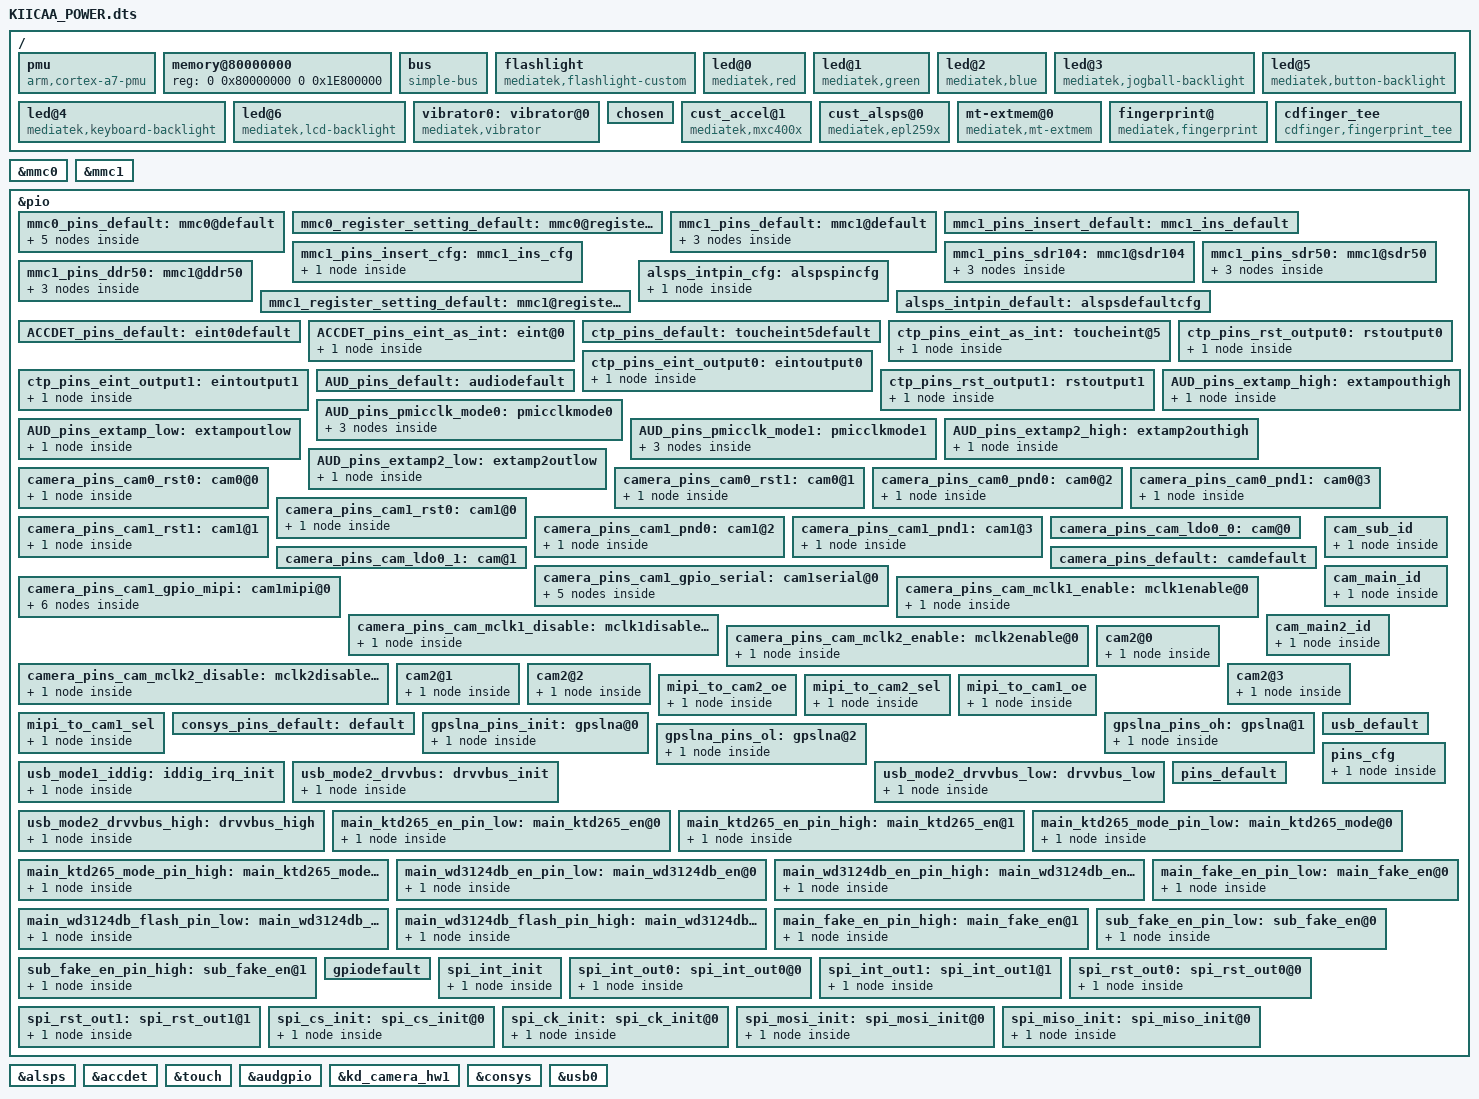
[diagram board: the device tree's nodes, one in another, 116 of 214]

/dts-v1/;

#include "mt6580.dtsi"

/ {
	pmu {
		compatible = "arm,cortex-a7-pmu";
		interrupts = <0x0 0x4 0x8 0x0 0x5 0x8 0x0 0x6 0x8 0x0 0x7 0x8>;
	};

	memory@80000000 {
		device_type = "memory";
		reg = <0 0x80000000 0 0x1E800000>;
	};

	bus {
		compatible = "simple-bus";
		#address-cells = <1>;
		#size-cells = <1>;
		ranges = <0 0 0 0xffffffff>;
	};
	flashlight:flashlight {
		compatible = "mediatek,flashlight-custom";
	};
	led@0 {
		compatible = "mediatek,red";
		led_mode = <3>;
		data = <2>;
		pwm_config = <0 0 0 0 0>;
	};
	led@1 {
		compatible = "mediatek,green";
		led_mode = <3>;
		data = <2>;
		pwm_config = <0 0 0 0 0>;
	};
	led@2 {
		compatible = "mediatek,blue";
		led_mode = <3>;
		data = <2>;
		pwm_config = <0 0 0 0 0>;
	};
	led@3 {
		compatible = "mediatek,jogball-backlight";
		led_mode = <0>;
		data = <1>;
		pwm_config = <0 0 0 0 0>;
	};
	led@4 {
		compatible = "mediatek,keyboard-backlight";
		led_mode = <0>;
		data = <1>;
		pwm_config = <0 0 0 0 0>;
	};
	led@5 {
		compatible = "mediatek,button-backlight";
		led_mode = <3>;
		data = <1>;
		pwm_config = <0 0 0 0 0>;
	};
	led@6 {
		compatible = "mediatek,lcd-backlight";
		led_mode = <5>;
		data = <1>;
		pwm_config = <0 0 0 0 0>;
	};

	vibrator0:vibrator@0 {
		compatible = "mediatek,vibrator";
		vib_timer = <25>;
		vib_limit = <9>;
		vib_vol= <6>;
	};

	   /* chosen */
	   chosen {
	bootargs = "console=tty0 console=ttyMT0,921600n1 root=/dev/ram initrd=0x84000000,0x400000 loglevel=8";
		/* fpga may has no lk, we need to specify display info here */
		/* fb buffer is reserved using this dts by memory node above */
		atag,videolfb-fb_base = <0x9E800000>;
		atag,videolfb-islcmfound = <1>;
		atag,videolfb-fps= <6000>;
		atag,videolfb-vramSize= <0x01800000>;
		atag,videolfb-lcmname= "nt35590_AUO";
	   };
	 /*  start sensor */
	cust_accel@1 {
		compatible = "mediatek,mxc400x";
		i2c_num 	= <0x2>;
		i2c_addr 	= <0x15 0x0 0x0 0x0>;
		direction 	= <0x3>;
		power_id 	= <0xffff>;
		power_vol 	= <0x0>;
		firlen 		= <0x0>;
		is_batch_supported = <0x0>;
	};

	cust_alsps@0 {
		compatible = "mediatek,epl259x";
		i2c_num = <0x2>;
		i2c_addr = <0x49 0x0 0x0 0x0>;
		polling_mode_ps = <0x0>;
		polling_mode_als = <0x1>;
		power_id = <0xffff>;
		power_vol = <0x0>;
		als_level = <0x0 0x7d 0x13f 0x20d 0x443 0x9b0 0xbf2 0x13fb 0x218d 0x2a11 0x3239 0x458f 0x564b 0xffff 0xffff>;
		als_value = <0x0 0x85 0x12f 0x1f8 0x3ea 0x7d3 0xbbe 0x138b 0x1f42 0x2710 0x2ee0 0x3e80 0x4e20 0x4e20 0x4e20 0x4e20>;
		ps_threshold_high = <0x1a>;
		ps_threshold_low = <0x15>;
		is_batch_supported_ps = <0x0>;
		is_batch_supported_als = <0x0>;
		ps_integration_time = <0x24>;
	};

	 /* end sensor */

	mt-extmem@0 {
		compatible = "mediatek,mt-extmem";
	};
	fingerprint@ {
		compatible = "mediatek,fingerprint";
		vfingerprint-supply = <0xe>;
		pinctrl-names = "default", "state_spi_eint_init", "state_eint_pull_down", "state_eint_pull_disable", "state_spi_rst_low", "state_spi_rst_high", "state_spi_cs_init", "state_spi_ck_init", "state_spi_mosi_init", "state_spi_miso_init";
		pinctrl-0 = <&gpiodefault>;
		pinctrl-1 = <&spi_int_init>;
		pinctrl-2 = <&spi_int_out0>;
		pinctrl-3 = <&spi_int_out1>;
		pinctrl-4 = <&spi_rst_out0>;
		pinctrl-5 = <&spi_int_out1>;
		pinctrl-6 = <&spi_cs_init>;
		pinctrl-7 = <&spi_ck_init>;
		pinctrl-8 = <&spi_mosi_init>;
		pinctrl-9 = <&spi_miso_init>;
		interrupt-parent = <&eintc>;
		interrupts = <0xf 0x2>;
		debounce = <0xf 0x0>;
		status = "okay";
	};

	cdfinger_tee {
		compatible = "cdfinger,fingerprint_tee";
	};
};

#include "KIICAA_POWER_bat_setting.dtsi"
/* mmc start */
&mmc0 {
	clk_src = /bits/ 8 <MSDC0_CLKSRC_208MHZ>;
	bus-width = <8>;
	max-frequency = <208000000>;
	cap-mmc-highspeed;
	msdc-sys-suspend;
	mmc-hs200-1_8v;
	non-removable;
	pinctl = <&mmc0_pins_default>;
	register_setting = <&mmc0_register_setting_default>;
	host_function = /bits/ 8 <MSDC_EMMC>;
	bootable;
	status = "okay";
};

&mmc1 {
	clk_src = /bits/ 8 <MSDC1_CLKSRC_187MHZ>;
	bus-width = <4>;
	max-frequency = <208000000>;
	msdc-sys-suspend;
	cap-sd-highspeed;
	sd-uhs-sdr12;
	sd-uhs-sdr25;
	sd-uhs-sdr50;
	sd-uhs-sdr104;
	pinctrl-names = "default","insert_cfg";
	pinctrl-0 = <&mmc1_pins_insert_default>;
	pinctrl-1 = <&mmc1_pins_insert_cfg>;
	pinctl = <&mmc1_pins_default>;
	pinctl_sdr104 = <&mmc1_pins_sdr104>;
	pinctl_sdr50 = <&mmc1_pins_sdr50>;
	pinctl_ddr50 = <&mmc1_pins_ddr50>;
	register_setting = <&mmc1_register_setting_default>;
	host_function = /bits/ 8 <MSDC_SD>;
	cd_level = /bits/ 8 <MSDC_CD_LOW>;
	cd-gpios = <&pio 3 0>;
	status = "okay";
	non-removable;
};

&pio {
	mmc0_pins_default: mmc0@default {
		pins_cmd {
			drive-strength = /bits/ 8 <2>;
		};
		pins_dat {
			drive-strength = /bits/ 8 <2>;
		};
		pins_clk {
			drive-strength = /bits/ 8 <2>;
		};
		pins_rst {
			drive-strength = /bits/ 8 <2>;
		};
		pins_ds {
			drive-strength = /bits/ 8 <2>;
		};
	};

	mmc0_register_setting_default: mmc0@register_default {
		dat0rddly      = /bits/ 8 <0>;
		dat1rddly      = /bits/ 8 <0>;
		dat2rddly      = /bits/ 8 <0>;
		dat3rddly      = /bits/ 8 <0>;
		dat4rddly      = /bits/ 8 <0>;
		dat5rddly      = /bits/ 8 <0>;
		dat6rddly      = /bits/ 8 <0>;
		dat7rddly      = /bits/ 8 <0>;
		datwrddly      = /bits/ 8 <0>;
		cmdrrddly      = /bits/ 8 <0>;
		cmdrddly       = /bits/ 8 <0>;
		cmd_edge = /bits/ 8 <MSDC_SMPL_FALLING>;
		rdata_edge = /bits/ 8 <MSDC_SMPL_FALLING>;
		wdata_edge = /bits/ 8 <MSDC_SMPL_FALLING>;

		ett-hs200-cells = <12>;
		ett-hs200-default = <OFFSET_MSDC_PATCH_BIT0	MSDC_PB0_INT_DAT_LATCH_CK_SEL 0x0
			OFFSET_MSDC_PATCH_BIT0  MSDC_PB0_CKGEN_MSDC_DLY_SEL   0x0
			OFFSET_MSDC_PATCH_BIT1  MSDC_PB1_CMD_RSP_TA_CNTR      0x1
			OFFSET_MSDC_IOCON       MSDC_IOCON_RSPL               0x1
			OFFSET_MSDC_PAD_TUNE0   MSDC_PAD_TUNE0_CMDRDLY        0x0
			OFFSET_MSDC_PAD_TUNE0   MSDC_PAD_TUNE0_CMDRRDLY       0x0
			OFFSET_MSDC_PATCH_BIT1  MSDC_PB1_WRDAT_CRCS_TA_CNTR   0x1
			OFFSET_MSDC_PAD_TUNE0   MSDC_PAD_TUNE0_DATWRDLY       0x0
			OFFSET_MSDC_IOCON       MSDC_IOCON_W_D_SMPL           0x1
			OFFSET_MSDC_DAT_RDDLY0  MSDC_DAT_RDDLY0_D0            0x0
			OFFSET_MSDC_PAD_TUNE0   MSDC_PAD_TUNE0_DATRRDLY       0x0
			OFFSET_MSDC_PATCH_BIT0  MSDC_PB0_RD_DAT_SEL           0x1>;
	};

	mmc1_pins_default: mmc1@default {
		pins_cmd {
			drive-strength = /bits/ 8 <3>;
		};
		pins_dat {
			drive-strength = /bits/ 8 <3>;
		};
		pins_clk {
			drive-strength = /bits/ 8 <3>;
		};
	};

	mmc1_pins_insert_default: mmc1_ins_default {
	};

	mmc1_pins_insert_cfg: mmc1_ins_cfg {
		pins_insert {
			pins = <PINMUX_GPIO34__FUNC_GPIO34>;
			input-schmitt-enable =<1>;
			slew-rate = <0>;
			bias-pull-up =<00>;
		};
	};

	mmc1_pins_sdr104: mmc1@sdr104 {
		pins_cmd {
			drive-strength = /bits/ 8 <2>;
		};
		pins_dat {
			drive-strength = /bits/ 8 <2>;
		};
		pins_clk {
			drive-strength = /bits/ 8 <3>;
		};
	};

	mmc1_pins_sdr50: mmc1@sdr50 {
		pins_cmd {
			drive-strength = /bits/ 8 <2>;
		};
		pins_dat {
			drive-strength = /bits/ 8 <2>;
		};
		pins_clk {
			drive-strength = /bits/ 8 <3>;
		};
	};

	mmc1_pins_ddr50: mmc1@ddr50 {
		pins_cmd {
			drive-strength = /bits/ 8 <2>;
		};
		pins_dat {
			drive-strength = /bits/ 8 <2>;
		};
		pins_clk {
			drive-strength = /bits/ 8 <3>;
		};
	};

	mmc1_register_setting_default: mmc1@register_default {
		dat0rddly      = /bits/ 8 <0>;
		dat1rddly      = /bits/ 8 <0>;
		dat2rddly      = /bits/ 8 <0>;
		dat3rddly      = /bits/ 8 <0>;
		datwrddly      = /bits/ 8 <0>;
		cmdrrddly      = /bits/ 8 <0>;
		cmdrddly       = /bits/ 8 <0>;
		cmd_edge = /bits/ 8 <MSDC_SMPL_FALLING>;
		rdata_edge = /bits/ 8 <MSDC_SMPL_FALLING>;
		wdata_edge = /bits/ 8 <MSDC_SMPL_FALLING>;
	};
};
/* mmc end */

&pio {
	alsps_intpin_cfg: alspspincfg {
	    pins_cmd_dat {
			pins = <PINMUX_GPIO18__FUNC_EINT2>;
			slew-rate = <0>;
			bias-pull-up = <00>;
		};
	};
	alsps_intpin_default: alspsdefaultcfg {
	};
};

&alsps {
	pinctrl-names = "pin_default", "pin_cfg";
	pinctrl-0 = <&alsps_intpin_default>;
	pinctrl-1 = <&alsps_intpin_cfg>;
	status = "okay";
};

&accdet {
	accdet-mic-vol = <7>;
	headset-mode-setting = <0x500 0x200 1 0x1F0 0x800 0x800 0x20>;
	accdet-plugout-debounce = <20>;
	/*1:ACC mode, 2:low cost without in bias, 6:low cost with in bias*/
	accdet-mic-mode = <1>;
	/*0--MD_MAX--UP_MAX--DW_MAX*/
	headset-three-key-threshold = <0 90 240 500>;
	/*0--MD_MAX--VOICE_MAX--UP_MAX--DW_MAX*/
	headset-four-key-threshold = <0x0 0x3c 0x7e 0xc9 0x1c2>;
	/* ACCDET GPIO standardization ACC mode use */
	pinctrl-names = "default", "state_eint_as_int";
	pinctrl-0 = <&ACCDET_pins_default>;
	pinctrl-1 = <&ACCDET_pins_eint_as_int>;
	status = "okay";
};

&flashlight{
};

&pio {
	ACCDET_pins_default: eint0default {
	};
	ACCDET_pins_eint_as_int: eint@0 {
		pins_cmd_dat {
			pins = <PINMUX_GPIO14__FUNC_EINT14>;
			slew-rate = <0>;
			bias-disable;
		};
	};
};
/*ACCDET END*/

/* TOUCH GPIO standardization */
&touch {
	tpd-resolution = <720 1280>;
	use-tpd-button = <1>;
	tpd-key-num = <0x3>;
	tpd-key-local = <0x8b 0xac 0x9e 0x0>;
	tpd-key-dim-local = <0x50 1350 0x64 0x28   0xf0 1350 0x64 0x28   0x190 1350 0x64 0x28   0x0 0x0 0x0 0x0>;
	tpd-max-touch-num = <0x5>;
	tpd-filter-enable = <0x0>;
	tpd-filter-pixel-density = <0x7c>;
	tpd-filter-custom-prameters = <0x0 0x0 0x0 0x0 0x0 0x0 0x0 0x0 0x0 0x0 0x0 0x0>;
	tpd-filter-custom-speed = <0x0 0x0 0x0>;
	pinctrl-names = "default", "state_eint_as_int", "state_eint_output0", "state_eint_output1",
		"state_rst_output0", "state_rst_output1";
	pinctrl-0 = <&ctp_pins_default>;
	pinctrl-1 = <&ctp_pins_eint_as_int>;
	pinctrl-2 = <&ctp_pins_eint_output0>;
	pinctrl-3 = <&ctp_pins_eint_output1>;
	pinctrl-4 = <&ctp_pins_rst_output0>;
	pinctrl-5 = <&ctp_pins_rst_output1>;
	status = "okay";
};
&pio {
	ctp_pins_default: toucheint5default {
	};
	ctp_pins_eint_as_int: toucheint@5 {
		pins_cmd_dat {
			pins = <PINMUX_GPIO5__FUNC_EINT5>;
			slew-rate = <0>;
			bias-disable;
		};
	};
	ctp_pins_eint_output0: eintoutput0 {
		pins_cmd_dat {
			pins = <PINMUX_GPIO5__FUNC_GPIO5>;
			slew-rate = <1>;
			output-low;
		};
	};
	ctp_pins_eint_output1: eintoutput1 {
		pins_cmd_dat {
			pins = <PINMUX_GPIO5__FUNC_GPIO5>;
			slew-rate = <1>;
			output-high;
		};
	};
	ctp_pins_rst_output0: rstoutput0 {
		pins_cmd_dat {
			pins = <PINMUX_GPIO6__FUNC_GPIO6>;
			slew-rate = <1>;
			output-low;
		};
	};
	ctp_pins_rst_output1: rstoutput1 {
		pins_cmd_dat {
			pins = <PINMUX_GPIO6__FUNC_GPIO6>;
			slew-rate = <1>;
			output-high;
		};
	};
};
/* TOUCH end */

/* AUDIO GPIO standardization */
&audgpio {

	pinctrl-names = "default", "audpmicclk-mode0", "audpmicclk-mode1",
			"extamp-pullhigh", "extamp-pulllow",
			"extamp2-pullhigh", "extamp2-pulllow";
	pinctrl-0 = <&AUD_pins_default>;
	pinctrl-1 = <&AUD_pins_pmicclk_mode0>;
	pinctrl-2 = <&AUD_pins_pmicclk_mode1>;
	pinctrl-3 = <&AUD_pins_extamp_high>;
	pinctrl-4 = <&AUD_pins_extamp_low>;
	pinctrl-5 = <&AUD_pins_extamp2_high>;
	pinctrl-6 = <&AUD_pins_extamp2_low>;
	status = "okay";
};
&pio {
	AUD_pins_default: audiodefault {
	};
	AUD_pins_pmicclk_mode0: pmicclkmode0 {
		pins_cmd0_dat {
			pins = <PINMUX_GPIO26__FUNC_GPIO26>;
		};
		pins_cmd1_dat {
			pins = <PINMUX_GPIO28__FUNC_GPIO28>;
		};
		pins_cmd2_dat {
			pins = <PINMUX_GPIO27__FUNC_GPIO27>;
		};
	};
	AUD_pins_pmicclk_mode1: pmicclkmode1 {
		pins_cmd0_dat {
			pins = <PINMUX_GPIO26__FUNC_AUD_CLK_MOSI>;
		};
		pins_cmd1_dat {
			pins = <PINMUX_GPIO28__FUNC_AUD_DAT_MISO>;
		};
		pins_cmd2_dat {
			pins = <PINMUX_GPIO27__FUNC_AUD_DAT_MOSI>;
		};
	};

	AUD_pins_extamp_high:extampouthigh {

		pins_cmd_dat {
			pins = <PINMUX_GPIO17__FUNC_GPIO17>;
			slew-rate = <1>;
			output-high;
		};
	};

	AUD_pins_extamp_low:extampoutlow {

		pins_cmd_dat {
			pins = <PINMUX_GPIO17__FUNC_GPIO17>;
			slew-rate = <1>;
			output-low;
		};
	};

	AUD_pins_extamp2_high:extamp2outhigh {
		pins_cmd_dat {
			pins = <PINMUX_GPIO17__FUNC_GPIO17>;
			slew-rate = <0x1>;
			output-high;
		};
	};

	AUD_pins_extamp2_low:extamp2outlow {
		pins_cmd_dat {
			pins = <PINMUX_GPIO17__FUNC_GPIO17>;
			slew-rate = <0x1>;
			output-low;
		};
	};
};
/* AUDIO end */

/* CAMERA GPIO standardization */
&pio {
	camera_pins_cam0_rst0: cam0@0 {
	    pins_cmd_dat {
			pins = <PINMUX_GPIO73__FUNC_GPIO73>;/*GPIO_CAMERA_CMRST_PIN*/
			slew-rate = <1>; /*direction 0:in, 1:out*/
			output-low;/*direction out used only. output_low or high*/
		};
	};
	camera_pins_cam0_rst1: cam0@1 {
	    pins_cmd_dat {
			pins = <PINMUX_GPIO73__FUNC_GPIO73>;/*GPIO_CAMERA_CMRST_PIN*/
			slew-rate = <1>;
			output-high;
		};
	};
	camera_pins_cam0_pnd0: cam0@2 {
	    pins_cmd_dat {
			pins = <PINMUX_GPIO71__FUNC_GPIO71>;/*GPIO_CAMERA_CMPDN_PIN*/
			slew-rate = <1>;
			output-low;
		};
	};
	camera_pins_cam0_pnd1: cam0@3 {
	    pins_cmd_dat {
			pins = <PINMUX_GPIO71__FUNC_GPIO71>;/*GPIO_CAMERA_CMPDN_PIN*/
			slew-rate = <1>;
			output-high;
		};
	};
	camera_pins_cam1_rst0: cam1@0 {
	    pins_cmd_dat {
			pins = <PINMUX_GPIO76__FUNC_GPIO76>;/*GPIO_CAMERA_CMRST1_PIN*/
			slew-rate = <1>; /*direction 0:in, 1:out*/
			output-low;/*direction out used only. output_low or high*/
		};
	};
	camera_pins_cam1_rst1: cam1@1 {
	    pins_cmd_dat {
			pins = <PINMUX_GPIO76__FUNC_GPIO76>;/*GPIO_CAMERA_CMRST1_PIN*/
			slew-rate = <1>;
			output-high;
		};
	};
	camera_pins_cam1_pnd0: cam1@2 {
	    pins_cmd_dat {
			pins = <PINMUX_GPIO74__FUNC_GPIO74>;/*GPIO_CAMERA_CMPDN1_PIN*/
			slew-rate = <1>;
			output-low;
		};
	};
	camera_pins_cam1_pnd1: cam1@3 {
	    pins_cmd_dat {
			pins = <PINMUX_GPIO74__FUNC_GPIO74>;/*GPIO_CAMERA_CMPDN1_PIN*/
			slew-rate = <1>;
			output-high;
		};
	};
	camera_pins_cam_ldo0_0: cam@0 {
	};
	camera_pins_cam_ldo0_1: cam@1 {
	};
	camera_pins_default: camdefault {
	};
	camera_pins_cam1_gpio_serial: cam1serial@0{
	    pins_cmd_dat {
			pins = <PINMUX_GPIO35__FUNC_CMCSK>;
		};
	    pins_cmd_dat1 {
			pins = <PINMUX_GPIO36__FUNC_CMCSD0>;
		};
	    pins_cmd_dat2 {
			pins = <PINMUX_GPIO37__FUNC_CMCSD1>;
		};
	    pins_cmd_dat3 {
			pins = <PINMUX_GPIO38__FUNC_CMCSD2>;
		};
	    pins_cmd_dat4 {
			pins = <PINMUX_GPIO39__FUNC_CMCSD3>;
		};
	};
	camera_pins_cam1_gpio_mipi: cam1mipi@0{
	    pins_cmd_dat {
			pins = <PINMUX_GPIO35__FUNC_PAD_RDP0_A>;
		};
	    pins_cmd_dat1 {
			pins = <PINMUX_GPIO36__FUNC_PAD_RDN0_A>;
		};
	    pins_cmd_dat2 {
			pins = <PINMUX_GPIO37__FUNC_PAD_RDP1_A>;
		};
	    pins_cmd_dat3 {
			pins = <PINMUX_GPIO38__FUNC_PAD_RDN1_A>;
		};
	    pins_cmd_dat4 {
			pins = <PINMUX_GPIO39__FUNC_PAD_RCP_A>;
		};
	    pins_cmd_dat5 {
			pins = <PINMUX_GPIO40__FUNC_PAD_RCN_A>;
		};
	};
	camera_pins_cam_mclk1_enable: mclk1enable@0{
		pins_cmd_dat {
			pins = <PINMUX_GPIO72__FUNC_CAM_CLK0>;
		};
	};
	camera_pins_cam_mclk1_disable: mclk1disable@0{
	   pins_cmd_dat {
			pins = <PINMUX_GPIO72__FUNC_GPIO72>;
		};
	};
	camera_pins_cam_mclk2_enable: mclk2enable@0{
		pins_cmd_dat {
			pins = <PINMUX_GPIO75__FUNC_CAM_CLK1>;
		};
	};
	camera_pins_cam_mclk2_disable: mclk2disable@0{
		pins_cmd_dat {
			pins = <PINMUX_GPIO75__FUNC_GPIO75>;
		};
	};
/***************************/
	cam_sub_id {
		pins_cmd_dat {
			pins = <PINMUX_GPIO21__FUNC_GPIO21>;
			slew-rate = <0x0>;
			bias-disable;
		};
	};

	cam_main_id {
		pins_cmd_dat {
			pins = <PINMUX_GPIO16__FUNC_GPIO16>;
			slew-rate = <0x0>;
			bias-disable;
		};
	};

	cam_main2_id {
		pins_cmd_dat {
			pins = <PINMUX_GPIO20__FUNC_GPIO20>;
			slew-rate = <0x0>;
			bias-disable;
		};
	};

	cam2@0 {
		pins_cmd_dat {
			pins = <PINMUX_GPIO7__FUNC_GPIO7>;
			slew-rate = <0x1>;
			output-low;
		};
	};

	cam2@1 {
		pins_cmd_dat {
			pins = <PINMUX_GPIO7__FUNC_GPIO7>;
			slew-rate = <0x1>;
			output-high;
		};
	};

	cam2@2 {
		pins_cmd_dat {
			pins = <PINMUX_GPIO8__FUNC_GPIO8>;
			slew-rate = <0x1>;
			output-low;
		};
	};

	cam2@3 {
		pins_cmd_dat {
			pins = <PINMUX_GPIO8__FUNC_GPIO8>;
			slew-rate = <0x1>;
			output-high;
		};
	};

	mipi_to_cam2_oe {
		pins_cmd_dat {
			pins = <PINMUX_GPIO83__FUNC_GPIO83>;
			slew-rate = <0x1>;
			output-low;
		};
	};

	mipi_to_cam2_sel {
		pins_cmd_dat {
			pins = <PINMUX_GPIO81__FUNC_GPIO81>;
			slew-rate = <0x1>;
			output-low;
		};
	};

	mipi_to_cam1_oe {
		pins_cmd_dat {
			pins = <PINMUX_GPIO83__FUNC_GPIO83>;
			slew-rate = <0x1>;
			output-low;
		};
	};

	mipi_to_cam1_sel {
		pins_cmd_dat {
			pins = <PINMUX_GPIO81__FUNC_GPIO81>;
			slew-rate = <0x1>;
			output-high;
		};
	};

};
&kd_camera_hw1 {
	pinctrl-names = "default", "cam0_rst0", "cam0_rst1", "cam0_pnd0", "cam0_pnd1",
				   "cam1_rst0", "cam1_rst1", "cam1_pnd0", "cam1_pnd1",
				   "cam_ldo0_0", "cam_ldo0_1", "cam1_gpio_serial", "cam1_gpio_mipi",
				   "cam_mclk1_enable","cam_mclk1_disable",
				   "cam_mclk2_enable","cam_mclk2_disable";
	pinctrl-0 = <&camera_pins_default>;
	pinctrl-1 = <&camera_pins_cam0_rst0>;
	pinctrl-2 = <&camera_pins_cam0_rst1>;
	pinctrl-3 = <&camera_pins_cam0_pnd0>;
	pinctrl-4 = <&camera_pins_cam0_pnd1>;
	pinctrl-5 = <&camera_pins_cam1_rst0>;
	pinctrl-6 = <&camera_pins_cam1_rst1>;
	pinctrl-7 = <&camera_pins_cam1_pnd0>;
	pinctrl-8 = <&camera_pins_cam1_pnd1>;
	pinctrl-9 = <&camera_pins_cam_ldo0_0>;
	pinctrl-10 = <&camera_pins_cam_ldo0_1>;
	pinctrl-11 = <&camera_pins_cam1_gpio_serial>;
	pinctrl-12 = <&camera_pins_cam1_gpio_mipi>;
	pinctrl-13 = <&camera_pins_cam_mclk1_enable>;
	pinctrl-14 = <&camera_pins_cam_mclk1_disable>;
	pinctrl-15 = <&camera_pins_cam_mclk2_enable>;
	pinctrl-16 = <&camera_pins_cam_mclk2_disable>;

	status = "okay";

};
/* CAMERA GPIO end */

/* CONSYS GPIO standardization */
&pio {
	consys_pins_default: default {

	};

	gpslna_pins_init: gpslna@0 {

		pins_cmd_dat {
			pins = <PINMUX_GPIO84__FUNC_GPIO84>;
			slew-rate = <0>;
			bias-disable;
			output-low;
		};
	};

	gpslna_pins_oh: gpslna@1 {

		pins_cmd_dat {
			pins = <PINMUX_GPIO84__FUNC_GPIO84>;
			slew-rate = <1>;
			output-high;
		};
	};

	gpslna_pins_ol: gpslna@2 {

		pins_cmd_dat {
			pins = <PINMUX_GPIO84__FUNC_GPIO84>;
			slew-rate = <1>;
			output-low;
		};
	};

};

&consys {
	pinctrl-names = "default", "gps_lna_state_init", "gps_lna_state_oh", "gps_lna_state_ol";
	pinctrl-0 = <&consys_pins_default>;
	pinctrl-1 = <&gpslna_pins_init>;
	pinctrl-2 = <&gpslna_pins_oh>;
	pinctrl-3 = <&gpslna_pins_ol>;
	status = "okay";

};

/* USB GPIO Kernal Standardization start */
&pio {
	usb_default: usb_default {
	};

	usb_mode1_iddig: iddig_irq_init {
		pins_cmd_dat {
			pins = <PINMUX_GPIO9__FUNC_EINT9>;
			slew-rate = <0>;
			bias-pull-up = <00>;
		};
	};

	usb_mode2_drvvbus: drvvbus_init {
		pins_cmd_dat {
			pins = <PINMUX_GPIO12__FUNC_GPIO12>;
			slew-rate = <1>;
			bias-pull-down = <00>;
		};
	};

	usb_mode2_drvvbus_low: drvvbus_low {
		pins_cmd_dat {
			pins = <PINMUX_GPIO12__FUNC_GPIO12>;
			slew-rate = <1>;
			output-low;
			bias-pull-down = <00>;
		};
	};

	usb_mode2_drvvbus_high: drvvbus_high {
		pins_cmd_dat {
			pins = <PINMUX_GPIO12__FUNC_GPIO12>;
			slew-rate = <1>;
			output-high;
			bias-pull-down = <00>;
		};
	};
};

&usb0{
	iddig_gpio = <0x9 0x6>;
	drvvbus_gpio = <0xc 0x0>;
	pinctrl-names = "usb_default", "iddig_irq_init", "drvvbus_init", "drvvbus_low", "drvvbus_high";
	pinctrl-0 = <&usb_default>;
	pinctrl-1 = <&usb_mode1_iddig>;
	pinctrl-2 = <&usb_mode2_drvvbus>;
	pinctrl-3 = <&usb_mode2_drvvbus_low>;
	pinctrl-4 = <&usb_mode2_drvvbus_high>;
	status = "okay";
};

/* CONSYS end */

&pio{
	pins_cfg {
		pins_cmd_dat {
			pins = <PINMUX_GPIO82__FUNC_EINT1>;
			slew-rate = <0x0>;
			bias-disable;
		};
	};

	pins_default {
	};
};
/* CAMERA */
&pio {
/*** main_ktd265 */
	main_ktd265_en_pin_low:main_ktd265_en@0 {
		pins_cmd_dat {
			pins = <PINMUX_GPIO10__FUNC_GPIO10>;
			slew-rate = <0x1>;
			output-low;
		};
	};

	main_ktd265_en_pin_high: main_ktd265_en@1 {
		pins_cmd_dat {
			pins = <PINMUX_GPIO10__FUNC_GPIO10>;
			slew-rate = <0x1>;
			output-high;
		};
	};

	main_ktd265_mode_pin_low: main_ktd265_mode@0 {
		pins_cmd_dat {
			pins = <PINMUX_GPIO11__FUNC_GPIO11>;
			slew-rate = <0x1>;
			output-low;
		};
	};

	main_ktd265_mode_pin_high: main_ktd265_mode@1 {
		pins_cmd_dat {
			pins = <PINMUX_GPIO11__FUNC_GPIO11>;
			slew-rate = <0x1>;
			output-high;
		};
	};
/*** FLASH ****************/
	main_wd3124db_en_pin_low: main_wd3124db_en@0 {
		pins_cmd_dat {
			pins = <PINMUX_GPIO10__FUNC_GPIO10>;
			slew-rate = <0x1>;
			output-low;
		};
	};

	main_wd3124db_en_pin_high: main_wd3124db_en@1 {
		pins_cmd_dat {
			pins = <PINMUX_GPIO10__FUNC_GPIO10>;
			slew-rate = <0x1>;
			output-high;
		};
	};

	main_wd3124db_flash_pin_low: main_wd3124db_flash@0 {
		pins_cmd_dat {
			pins = <PINMUX_GPIO11__FUNC_GPIO11>;
			slew-rate = <0x1>;
			output-low;
		};
	};

	main_wd3124db_flash_pin_high: main_wd3124db_flash@1 {
		pins_cmd_dat {
			pins = <PINMUX_GPIO11__FUNC_GPIO11>;
			slew-rate = <0x1>;
			output-high;
		};
	};
/*** FAKE FRONT CANERA *****************/
	main_fake_en_pin_low: main_fake_en@0 {
		pins_cmd_dat {
			pins = <PINMUX_GPIO4__FUNC_GPIO4>;
			slew-rate = <0x1>;
			output-low;
		};
	};

	main_fake_en_pin_high: main_fake_en@1 {
		pins_cmd_dat {
			pins = <PINMUX_GPIO4__FUNC_GPIO4>;
			slew-rate = <0x1>;
			output-high;
		};
	};

	sub_fake_en_pin_low: sub_fake_en@0 {
		pins_cmd_dat {
			pins = <PINMUX_GPIO9__FUNC_GPIO9>;
			slew-rate = <0x1>;
			output-low;
		};
	};

	sub_fake_en_pin_high: sub_fake_en@1 {
		pins_cmd_dat {
			pins = <PINMUX_GPIO9__FUNC_GPIO9>;
			slew-rate = <0x1>;
			output-high;
		};
	};
};

/******* SPI FINGERPRINT *******/
&pio {
	gpiodefault: gpiodefault {
	};

	spi_int_init: spi_int_init {
		pins_cmd_dat {
			pins = <PINMUX_GPIO15__FUNC_EINT15>;
			slew-rate = <0x0>;
			bias-disable;
		};
	};

	spi_int_out0: spi_int_out0@0 {
		pins_cmd_dat {
			pins = <PINMUX_GPIO15__FUNC_GPIO15>;
			slew-rate = <0x1>;
			output-low;
		};
	};

	spi_int_out1: spi_int_out1@1 {
		pins_cmd_dat {
			pins = <PINMUX_GPIO15__FUNC_GPIO15>;
			slew-rate = <0x1>;
			output-high;
		};
	};

	spi_rst_out0: spi_rst_out0@0 {
		pins_cmd_dat {
			pins = <PINMUX_GPIO19__FUNC_GPIO19>;
			slew-rate = <0x1>;
			output-low;
		};
	};

	spi_rst_out1: spi_rst_out1@1 {
		pins_cmd_dat {
			pins = <PINMUX_GPIO19__FUNC_GPIO19>;
			slew-rate = <0x1>;
			output-high;
		};
	};

	spi_cs_init: spi_cs_init@0 {
		pins_cmd_dat {
			pins = <PINMUX_GPIO0__FUNC_SPI1_CS>;
			slew-rate = <0x1>;
			bias-pull-up = <0x0>;
		};
	};

	spi_ck_init: spi_ck_init@0 {
		pins_cmd_dat {
			pins = <PINMUX_GPIO1__FUNC_SPI1_SCK>;
			slew-rate = <0x1>;
			bias-pull-up = <0x0>;
		};
	};

	spi_mosi_init: spi_mosi_init@0 {
		pins_cmd_dat {
			pins = <PINMUX_GPIO2__FUNC_SPI1_MOSI>;
			slew-rate = <0x1>;
			bias-pull-up = <0x0>;
		};
	};

	spi_miso_init: spi_miso_init@0 {
		pins_cmd_dat {
			pins = <PINMUX_GPIO3__FUNC_SPI1_MISO>;
			slew-rate = <0x0>;
			bias-pull-up = <0x0>;
		};
	};
};
/* FLASH */
&flashlight
{
	flashlight_main_support = <0x1 0x3>;
	flashlight_sub_support = <0x1 0x1>;
	flashlight_isnk_num = <0x0 0x0 0x1 0x1>;
	pinctrl-names = "default", "main_ktd265_en_pin_low", "main_ktd265_en_pin_high",
			"main_ktd265_mode_pin_low", "main_ktd265_mode_pin_high",
			"main_wd3124db_en_pin_low", "main_wd3124db_en_pin_high",
			"main_wd3124db_flash_pin_low", "main_wd3124db_flash_pin_high",
			"main_fake_en_pin_low", "main_fake_en_pin_high",
			"sub_fake_en_pin_low", "sub_fake_en_pin_high";
	pinctrl-0 = <&camera_pins_default>;
	pinctrl-1 = <&main_ktd265_en_pin_low>;
	pinctrl-2 = <&main_ktd265_en_pin_high>;
	pinctrl-3 = <&main_ktd265_mode_pin_low>;
	pinctrl-4 = <&main_ktd265_mode_pin_high>;
	pinctrl-5 = <&main_wd3124db_en_pin_low>;
	pinctrl-6 = <&main_wd3124db_en_pin_high>;
	pinctrl-7 = <&main_wd3124db_flash_pin_low>;
	pinctrl-8 = <&main_wd3124db_flash_pin_high>;
	pinctrl-9 = <&main_fake_en_pin_low>;
	pinctrl-10 = <&main_fake_en_pin_high>;
	pinctrl-11 = <&sub_fake_en_pin_low>;
	pinctrl-12 = <&sub_fake_en_pin_high>;
	status = "okay";
};
